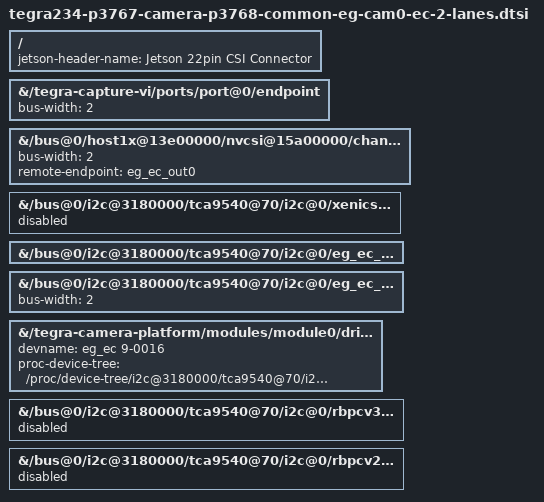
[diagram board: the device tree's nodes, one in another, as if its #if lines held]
// SPDX-License-Identifier: GPL-2.0-only

/*
 * Shared body for tegra234-p3767-camera-p3768-eg-cam0-ec-2-lanes.dts
 * (generic/Forecr/devkit topology, cam_i2cmux GPIO mux) and its Hadron
 * DM counterpart tegra234-p3767-camera-p3768-cti-eg-cam0-ec-2-lanes.dts
 * (chip-based tca9540@70 I2C mux instead of cam_i2cmux) — same
 * HADRON_DM_CAM_I2C_MUX distinction as
 * tegra234-p3767-camera-common-eg-cams-dione.dtsi.
 */

/dts-v1/;
/plugin/;

#include <dt-bindings/tegra234-p3767-0000-common.h>

/*
 * Mode paths vary on two INDEPENDENT axes, and they must stay independent:
 *
 *   - the I2C mux -- a real PCA9540 chip on Hadron DM, a GPIO-toggled
 *     cam_i2cmux everywhere else (HADRON_DM_CAM_I2C_MUX);
 *   - the mode numbering -- PRISTINE_KERNEL drops the two RAW16 modes,
 *     which the vendor's precompiled kernel cannot negotiate, and shifts
 *     the survivors down (see drivers/media/i2c/eg_ec_mipi_src.c and
 *     tegra234-p3767-camera-common-eg-cams-dione.dtsi, which renumbers the
 *     mode nodes themselves).
 *
 * They used to be nested, with the renumbering written only inside the
 * Hadron DM branch. A PRISTINE_KERNEL build on any other carrier therefore
 * kept targeting mode4/mode5 -- nodes that build does not define -- and put
 * the wrong pixel clocks on the two modes that did exist. Naming each mode
 * by what it IS, rather than by a number that means different things in
 * different builds, is what keeps the two axes from re-entangling.
 */
#ifdef HADRON_DM_CAM_I2C_MUX
#ifndef PRISTINE_KERNEL
#define EG_EC_640_RAW16   "/bus@0/i2c@3180000/tca9540@70/i2c@0/eg_ec_b@16/mode0"
#define EG_EC_640_RGB888  "/bus@0/i2c@3180000/tca9540@70/i2c@0/eg_ec_b@16/mode1"
#define EG_EC_640_YUYV    "/bus@0/i2c@3180000/tca9540@70/i2c@0/eg_ec_b@16/mode2"
#define EG_EC_1280_RAW16  "/bus@0/i2c@3180000/tca9540@70/i2c@0/eg_ec_b@16/mode3"
#define EG_EC_1280_RGB888 "/bus@0/i2c@3180000/tca9540@70/i2c@0/eg_ec_b@16/mode4"
#define EG_EC_1280_YUYV   "/bus@0/i2c@3180000/tca9540@70/i2c@0/eg_ec_b@16/mode5"
#else
#define EG_EC_640_RGB888  "/bus@0/i2c@3180000/tca9540@70/i2c@0/eg_ec_b@16/mode0"
#define EG_EC_640_YUYV    "/bus@0/i2c@3180000/tca9540@70/i2c@0/eg_ec_b@16/mode1"
#define EG_EC_1280_RGB888 "/bus@0/i2c@3180000/tca9540@70/i2c@0/eg_ec_b@16/mode2"
#define EG_EC_1280_YUYV   "/bus@0/i2c@3180000/tca9540@70/i2c@0/eg_ec_b@16/mode3"
#endif
#else
#ifndef PRISTINE_KERNEL
#define EG_EC_640_RAW16   "/bus@0/cam_i2cmux/i2c@0/eg_ec_b@16/mode0"
#define EG_EC_640_RGB888  "/bus@0/cam_i2cmux/i2c@0/eg_ec_b@16/mode1"
#define EG_EC_640_YUYV    "/bus@0/cam_i2cmux/i2c@0/eg_ec_b@16/mode2"
#define EG_EC_1280_RAW16  "/bus@0/cam_i2cmux/i2c@0/eg_ec_b@16/mode3"
#define EG_EC_1280_RGB888 "/bus@0/cam_i2cmux/i2c@0/eg_ec_b@16/mode4"
#define EG_EC_1280_YUYV   "/bus@0/cam_i2cmux/i2c@0/eg_ec_b@16/mode5"
#else
#define EG_EC_640_RGB888  "/bus@0/cam_i2cmux/i2c@0/eg_ec_b@16/mode0"
#define EG_EC_640_YUYV    "/bus@0/cam_i2cmux/i2c@0/eg_ec_b@16/mode1"
#define EG_EC_1280_RGB888 "/bus@0/cam_i2cmux/i2c@0/eg_ec_b@16/mode2"
#define EG_EC_1280_YUYV   "/bus@0/cam_i2cmux/i2c@0/eg_ec_b@16/mode3"
#endif
#endif

/ {
	#ifdef EG_CSI_22PIN
	jetson-header-name = "Jetson 22pin CSI Connector";
#else
	jetson-header-name = "Jetson 24pin CSI Connector";
#endif
	compatible = JETSON_COMPATIBLE_P3768;

	fragment@10 {
		target-path = "/tegra-capture-vi/ports/port@0/endpoint";
		__overlay__ {
			bus-width=<2>;
		};
	};

	fragment@11 {
		target-path = "/bus@0/host1x@13e00000/nvcsi@15a00000/channel@0/ports/port@0/endpoint@0";
		__overlay__ {
			bus-width=<2>;
         remote-endpoint = <&eg_ec_out0>;
		};
	};

   // Disable Dione cameras
	fragment@12 {
		#ifdef HADRON_DM_CAM_I2C_MUX
		target-path = "/bus@0/i2c@3180000/tca9540@70/i2c@0/xenics_dione_ir_b@0e";
		#else
		target-path = "/bus@0/cam_i2cmux/i2c@0/xenics_dione_ir_b@0e";
		#endif
		__overlay__ {
         status = "disabled";
		};
	};

   // Enable EngineCore cameras
	fragment@13 {
		#ifdef HADRON_DM_CAM_I2C_MUX
		target-path = "/bus@0/i2c@3180000/tca9540@70/i2c@0/eg_ec_b@16";
		#else
		target-path = "/bus@0/cam_i2cmux/i2c@0/eg_ec_b@16";
		#endif
		__overlay__ {
         status = "okay";
		};
	};
#ifndef PRISTINE_KERNEL
	fragment@14 {
		target-path = EG_EC_640_RAW16;
		__overlay__ {
         num_lanes = "2";
         pix_clk_hz = "100000000";
		};
	};
#endif
	fragment@15 {
		target-path = EG_EC_640_RGB888;
		__overlay__ {
         num_lanes = "2";
         pix_clk_hz = "100000000";
		};
	};
	fragment@16 {
		target-path = EG_EC_640_YUYV;
		__overlay__ {
         num_lanes = "2";
         pix_clk_hz = "100000000";
		};
	};
#ifndef PRISTINE_KERNEL
	fragment@17 {
		target-path = EG_EC_1280_RAW16;
		__overlay__ {
         num_lanes = "2";
         pix_clk_hz = "100000000";
		};
	};
#endif
	fragment@18 {
		target-path = EG_EC_1280_RGB888;
		__overlay__ {
         num_lanes = "2";
         pix_clk_hz = "133333336";
		};
	};
	fragment@19 {
		target-path = EG_EC_1280_YUYV;
		__overlay__ {
         num_lanes = "2";
         pix_clk_hz = "100000000";
		};
	};
	fragment@20 {
		#ifdef HADRON_DM_CAM_I2C_MUX
		target-path = "/bus@0/i2c@3180000/tca9540@70/i2c@0/eg_ec_b@16/ports/port@0/endpoint";
		#else
		target-path = "/bus@0/cam_i2cmux/i2c@0/eg_ec_b@16/ports/port@0/endpoint";
		#endif
		__overlay__ {
			bus-width=<2>;
		};
	};

	fragment@21 {
		target-path = "/tegra-camera-platform/modules/module0/drivernode0";
		__overlay__ {
         devname = "eg_ec 9-0016";
			#ifdef HADRON_DM_CAM_I2C_MUX
			proc-device-tree = "/proc/device-tree/i2c@3180000/tca9540@70/i2c@0/eg_ec_b@16";
			#else
			proc-device-tree = "/proc/device-tree/cam_i2cmux/i2c@0/eg_ec_b@16";
			#endif
		};
	};

  // Disable other cameras 
	fragment@30 {
		#ifdef HADRON_DM_CAM_I2C_MUX
		target-path = "/bus@0/i2c@3180000/tca9540@70/i2c@0/rbpcv3_imx477_a@1a";
		#else
		target-path = "/bus@0/cam_i2cmux/i2c@0/rbpcv3_imx477_a@1a";
		#endif
		__overlay__ {
         status = "disabled";
		};
	};
	fragment@31 {
		#ifdef HADRON_DM_CAM_I2C_MUX
		target-path = "/bus@0/i2c@3180000/tca9540@70/i2c@0/rbpcv2_imx219_a@10";
		#else
		target-path = "/bus@0/cam_i2cmux/i2c@0/rbpcv2_imx219_a@10";
		#endif
		__overlay__ {
         status = "disabled";
		};
	};


};
